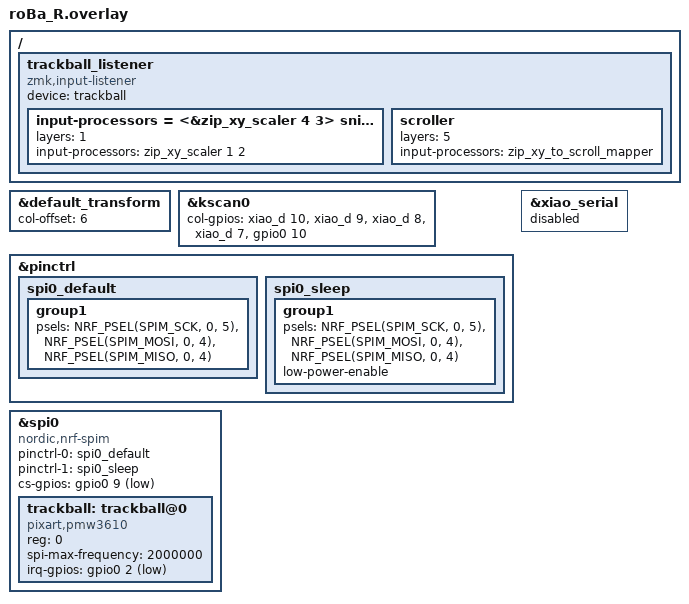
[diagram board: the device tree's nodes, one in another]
#include "roBa.dtsi"
#include <input/processors.dtsi>

/* 1. レイヤー自動遷移の設定：コメントアウト */
/* &zip_temp_layer {
    excluded-positions = <
        18 // J
        20 // L
        33 // Shift
        45 // ctrl
    >;
    require-prior-idle-ms = <400>;
};
*/

/* 2. 入力リスナーの設定 */
/ {
    trackball_listener: trackball_listener {
        compatible = "zmk,input-listener";
        device = <&trackball>;
        status = "okay";

        /* デフォルト：感度調整のみ残し、 <&zip_temp_layer 4 10000>をコメントアウト */
        input-processors = 
            <&zip_xy_scaler 4 3>/*;

        /* スナイプモード（レイヤー1） */
        snipe {
            layers = <1>;
            input-processors = <&zip_xy_scaler 1 2>;
        };

        /* スクロールモード（レイヤー5） */
        scroller {
            layers = <5>;
            input-processors = <&zip_xy_to_scroll_mapper>;
        };
    };
};

/* --- 以下、ハードウェア固有設定（そのまま維持） --- */
&default_transform { col-offset = <6>; };

&kscan0 {
    col-gpios
        = <&xiao_d 10 GPIO_ACTIVE_HIGH>
        , <&xiao_d 9 GPIO_ACTIVE_HIGH>
        , <&xiao_d 8 GPIO_ACTIVE_HIGH>
        , <&xiao_d 7 GPIO_ACTIVE_HIGH>
        , <&gpio0 10 GPIO_ACTIVE_HIGH>
        ;
};

&pinctrl {
    spi0_default: spi0_default {
        group1 {
            psels = <NRF_PSEL(SPIM_SCK, 0, 5)>,
                <NRF_PSEL(SPIM_MOSI, 0, 4)>,
                <NRF_PSEL(SPIM_MISO, 0, 4)>;
        };
    };
    spi0_sleep: spi0_sleep {
        group1 {
            psels = <NRF_PSEL(SPIM_SCK, 0, 5)>,
                <NRF_PSEL(SPIM_MOSI, 0, 4)>,
                <NRF_PSEL(SPIM_MISO, 0, 4)>;
            low-power-enable;
        };
    };
};

&xiao_serial { status = "disabled"; };

&spi0 {
    status = "okay";
    compatible = "nordic,nrf-spim";
    pinctrl-0 = <&spi0_default>;
    pinctrl-1 = <&spi0_sleep>;
    pinctrl-names = "default", "sleep";
    cs-gpios = <&gpio0 9 GPIO_ACTIVE_LOW>;

    trackball: trackball@0 {
        status = "okay";
        compatible = "pixart,pmw3610";
        reg = <0>;
        spi-max-frequency = <2000000>;
        irq-gpios = <&gpio0 2 (GPIO_ACTIVE_LOW | GPIO_PULL_UP)>;
    };
};
